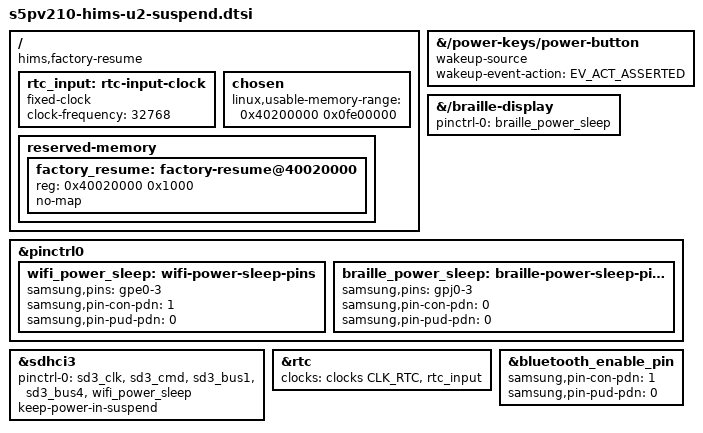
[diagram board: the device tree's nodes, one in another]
// SPDX-License-Identifier: GPL-2.0-only
#include <dt-bindings/input/gpio-keys.h>
/* The retained first-stage loader wakes at fixed physical 0x40020000. */
/ {
    hims,factory-resume;
    rtc_input: rtc-input-clock {
        /* Unmanaged 32.768 kHz input; no PMIC programming is implied. */
        compatible = "fixed-clock";
        #clock-cells = <0>;
        clock-frequency = <32768>;
    };
    chosen {
        linux,usable-memory-range = <0x40200000 0x0fe00000>;
    };
    reserved-memory {
        #address-cells = <1>;
        #size-cells = <1>;
        ranges;
        factory_resume: factory-resume@40020000 {
            reg = <0x40020000 0x1000>;
            no-map;
        };
    };
};

&{/power-keys/power-button} {
    wakeup-source;
    wakeup-event-action = <EV_ACT_ASSERTED>;
};

&{/braille-display} {
    pinctrl-names = "default";
    pinctrl-0 = <&braille_power_sleep>;
};

&pinctrl0 {
    wifi_power_sleep: wifi-power-sleep-pins {
        samsung,pins = "gpe0-3";
        /* MMC_PM_KEEP_POWER also requires the board enable to stay high. */
        samsung,pin-con-pdn = <1>;
        samsung,pin-pud-pdn = <0>;
    };
    braille_power_sleep: braille-power-sleep-pins {
        samsung,pins = "gpj0-3";
        /* Drive low during sleep; do not alter its live mux/output. */
        samsung,pin-con-pdn = <0>;
        samsung,pin-pud-pdn = <0>;
    };
};

/* Retain RTL8712 firmware, without enabling an SDIO wake source. */
&sdhci3 {
    pinctrl-0 = <&sd3_clk &sd3_cmd &sd3_bus1 &sd3_bus4 &wifi_power_sleep>;
    keep-power-in-suspend;
};

/* Wall-clock retention only; alarm wake is disabled by board policy. */
&rtc {
    status = "okay";
    clocks = <&clocks CLK_RTC>, <&rtc_input>;
    clock-names = "rtc", "rtc_src";
};

/* Preserve volatile CSR parameters across sleep; UART is not a wake source. */
&bluetooth_enable_pin {
    samsung,pin-con-pdn = <1>;
    samsung,pin-pud-pdn = <0>;
};
